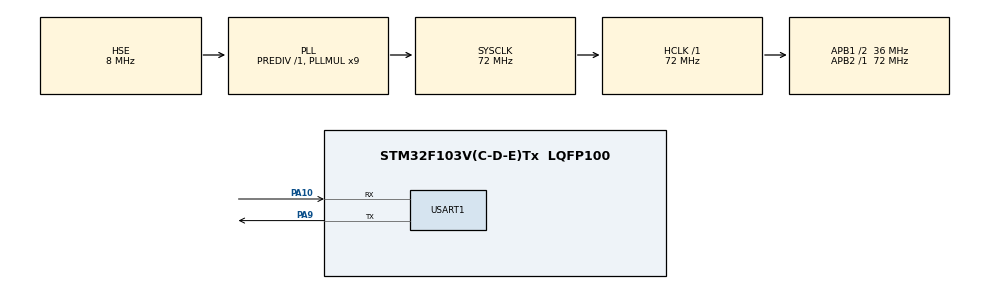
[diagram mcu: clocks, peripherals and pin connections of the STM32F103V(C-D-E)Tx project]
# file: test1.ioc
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FREERTOS.Tasks01=defaultTask,24,128,StartDefaultTask,Default,NULL,Dynamic,NULL,NULL
Mcu.Family=STM32F1
Mcu.Name=STM32F103V(C-D-E)Tx
Mcu.Package=LQFP100
NVIC.PriorityGroup=NVIC_PRIORITYGROUP_4
NVIC.TIM6_IRQn=true\:15\:0\:false\:false\:true\:false\:false\:true\:true
NVIC.TimeBase=TIM6_IRQn
NVIC.TimeBaseIP=TIM6
OSC_IN.Mode=HSE-External-Oscillator
OSC_IN.Signal=RCC_OSC_IN
OSC_OUT.Mode=HSE-External-Oscillator
OSC_OUT.Signal=RCC_OSC_OUT
PA10.Mode=Asynchronous
PA10.Signal=USART1_RX
PA13.Mode=Serial_Wire
PA13.Signal=SYS_JTMS-SWDIO
PA14.Mode=Serial_Wire
PA14.Signal=SYS_JTCK-SWCLK
PA9.Mode=Asynchronous
PA9.Signal=USART1_TX
PC14-OSC32_IN.Mode=LSE-External-Oscillator
PC14-OSC32_IN.Signal=RCC_OSC32_IN
PC15-OSC32_OUT.Mode=LSE-External-Oscillator
PC15-OSC32_OUT.Signal=RCC_OSC32_OUT
ProjectManager.HeapSize=0x200
ProjectManager.StackSize=0x400
ProjectManager.TargetToolchain=MDK-ARM V5.32
RCC.AHBFreq_Value=72000000
RCC.APB1CLKDivider=RCC_HCLK_DIV2
RCC.APB1Freq_Value=36000000
RCC.APB1TimFreq_Value=72000000
RCC.APB2Freq_Value=72000000
RCC.APB2TimFreq_Value=72000000
RCC.HCLKFreq_Value=72000000
RCC.PLLMUL=RCC_PLL_MUL9
RCC.PLLSourceVirtual=RCC_PLLSOURCE_HSE
RCC.SYSCLKFreq_VALUE=72000000
RCC.SYSCLKSource=RCC_SYSCLKSOURCE_PLLCLK
RCC.USBFreq_Value=72000000
USART1.VirtualMode=VM_ASYNC
VP_FREERTOS_VS_CMSIS_V2.Mode=CMSIS_V2
VP_SYS_VS_tim6.Mode=TIM6
board=custom

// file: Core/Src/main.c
/* USER CODE BEGIN Header */
/**
  ******************************************************************************
  * @file           : main.c
  * @brief          : Main program body
  ******************************************************************************
  * @attention
  *
  * Copyright (c) 2025 STMicroelectronics.
  * All rights reserved.
  *
  * This software is licensed under terms that can be found in the LICENSE file
  * in the root directory of this software component.
  * If no LICENSE file comes with this software, it is provided AS-IS.
  *
  ******************************************************************************
  */
/* USER CODE END Header */
#include "main.h"
#include "cmsis_os.h"
#include "usart.h"
#include "gpio.h"

void SystemClock_Config(void);
void MX_FREERTOS_Init(void);

int main(void)
{

    /* MCU Configuration--------------------------------------------------------*/

    /* Reset of all peripherals, Initializes the Flash interface and the Systick. */
    HAL_Init();

    /* Configure the system clock */
    SystemClock_Config();

    /* Initialize all configured peripherals */
    MX_GPIO_Init();
    MX_USART1_UART_Init();
    /* USER CODE BEGIN 2 */
    //printf("123\r\n");
    /* USER CODE END 2 */

    /* Init scheduler */
    osKernelInitialize();

    /* Call init function for freertos objects (in cmsis_os2.c) */
    MX_FREERTOS_Init();

    /* Start scheduler */
    osKernelStart();

    /* We should never get here as control is now taken by the scheduler */

    /* Infinite loop */
    while (1)
    {

    }
}

void SystemClock_Config(void)
{
    RCC_OscInitTypeDef RCC_OscInitStruct = {0};
    RCC_ClkInitTypeDef RCC_ClkInitStruct = {0};

    /** Initializes the RCC Oscillators according to the specified parameters
    * in the RCC_OscInitTypeDef structure.
    */
    RCC_OscInitStruct.OscillatorType = RCC_OSCILLATORTYPE_HSE;
    RCC_OscInitStruct.HSEState = RCC_HSE_ON;
    RCC_OscInitStruct.HSEPredivValue = RCC_HSE_PREDIV_DIV1;
    RCC_OscInitStruct.HSIState = RCC_HSI_ON;
    RCC_OscInitStruct.PLL.PLLState = RCC_PLL_ON;
    RCC_OscInitStruct.PLL.PLLSource = RCC_PLLSOURCE_HSE;
    RCC_OscInitStruct.PLL.PLLMUL = RCC_PLL_MUL9;
    if (HAL_RCC_OscConfig(&RCC_OscInitStruct) != HAL_OK)
    {
        Error_Handler();
    }

    /** Initializes the CPU, AHB and APB buses clocks
    */
    RCC_ClkInitStruct.ClockType = RCC_CLOCKTYPE_HCLK|RCC_CLOCKTYPE_SYSCLK
                                  |RCC_CLOCKTYPE_PCLK1|RCC_CLOCKTYPE_PCLK2;
    RCC_ClkInitStruct.SYSCLKSource = RCC_SYSCLKSOURCE_PLLCLK;
    RCC_ClkInitStruct.AHBCLKDivider = RCC_SYSCLK_DIV1;
    RCC_ClkInitStruct.APB1CLKDivider = RCC_HCLK_DIV2;
    RCC_ClkInitStruct.APB2CLKDivider = RCC_HCLK_DIV1;

    if (HAL_RCC_ClockConfig(&RCC_ClkInitStruct, FLASH_LATENCY_2) != HAL_OK)
    {
        Error_Handler();
    }
}

void HAL_TIM_PeriodElapsedCallback(TIM_HandleTypeDef *htim)
{
    if (htim->Instance == TIM6) {
        HAL_IncTick();
    }
}

void Error_Handler(void)
{
    __disable_irq();
    while (1)
    {
    }
}

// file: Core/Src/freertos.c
/* USER CODE BEGIN Header */
/**
  ******************************************************************************
  * File Name          : freertos.c
  * Description        : Code for freertos applications
  ******************************************************************************
  * @attention
  *
  * Copyright (c) 2025 STMicroelectronics.
  * All rights reserved.
  *
  * This software is licensed under terms that can be found in the LICENSE file
  * in the root directory of this software component.
  * If no LICENSE file comes with this software, it is provided AS-IS.
  *
  ******************************************************************************
  */
/* USER CODE END Header */

#include "FreeRTOS.h"
#include "task.h"
#include "main.h"
#include "cmsis_os.h"

/* USER CODE BEGIN Includes */
#include "stdio.h"
/* USER CODE END Includes */

/* USER CODE BEGIN Variables */
static TaskHandle_t Task1_Handle = NULL;
static TaskHandle_t Task2_Handle = NULL;

/* USER CODE END Variables */
/* Definitions for defaultTask */
osThreadId_t defaultTaskHandle;
const osThreadAttr_t defaultTask_attributes = {
    .name = "defaultTask",
    .stack_size = 128 * 4,
    .priority = (osPriority_t) osPriorityNormal,
};

/* USER CODE BEGIN FunctionPrototypes */
void Task1(void *args);
void Task2(void *args);
/* USER CODE END FunctionPrototypes */

void StartDefaultTask(void *argument);

void MX_FREERTOS_Init(void); /* (MISRA C 2004 rule 8.1) */

void MX_FREERTOS_Init(void) {

    /* Create the thread(s) */
    /* creation of defaultTask */
    defaultTaskHandle = osThreadNew(StartDefaultTask, NULL, &defaultTask_attributes);

}

void StartDefaultTask(void *argument)
{
    /* USER CODE BEGIN StartDefaultTask */
    xTaskCreate((TaskFunction_t)Task1,
                (const char *)"TASK1",
                (configSTACK_DEPTH_TYPE)128,
                (void *)NULL,
                (UBaseType_t)osPriorityNormal,
                (TaskHandle_t *)&Task1_Handle);
    xTaskCreate((TaskFunction_t)Task2,
                (const char *)"TASK2",
                (configSTACK_DEPTH_TYPE)128,
                (void *)NULL,
                (UBaseType_t)osPriorityNormal,
                (TaskHandle_t *)&Task2_Handle);

		vTaskDelete(NULL);
    /* Infinite loop */
    for(;;)
    {
        //osDelay(1);
    }
    /* USER CODE END StartDefaultTask */
}

/* USER CODE BEGIN Application */
void Task1(void *args)
{
    uint8_t num=0;
    while(1) {
        if(num>=255)num=0;
        taskENTER_CRITICAL();
        printf("229064049,num = %d\r\n",++num);
        taskEXIT_CRITICAL();
        vTaskDelay(1000);
    }

}

void Task2(void *args)
{
    uint8_t num=0;
    while(1) {
        taskENTER_CRITICAL();
        printf("2025-04-16\r\n");
        taskEXIT_CRITICAL();
        vTaskDelay(1000);
        num++;
        if(num>=3)vTaskDelete(NULL);
    }

}
/* USER CODE END Application */
